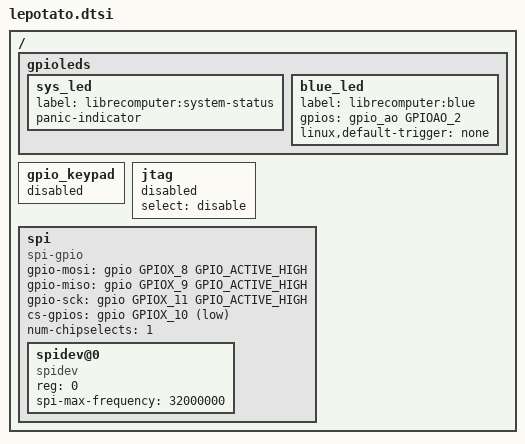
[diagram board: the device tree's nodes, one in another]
/* Stuff common to le potato */

/ {
	gpioleds {
		sys_led {
			label = "librecomputer:system-status";
			panic-indicator;
		};

		blue_led {
			label = "librecomputer:blue";
			gpios = <&gpio_ao GPIOAO_2 GPIO_ACTIVE_HIGH>;
			linux,default-trigger = "none";
		};
	};

	gpio_keypad {
		status = "disabled";
	};

	/delete-node/ mtd_nand;

	jtag {
		status = "disabled";
		select = "disable";
	};

	spi {
		compatible = "spi-gpio";
		ranges;

		gpio-mosi = <&gpio GPIOX_8 GPIO_ACTIVE_HIGH>;
		gpio-miso = <&gpio GPIOX_9 GPIO_ACTIVE_HIGH>;
		gpio-sck = <&gpio GPIOX_11 GPIO_ACTIVE_HIGH>;
		cs-gpios = <&gpio GPIOX_10 GPIO_ACTIVE_LOW>;
		num-chipselects = <1>;
		status = "ok";

		spidev@0 {
			compatible = "spidev";
			reg = <0>;
			spi-max-frequency = <32000000>;
			status = "okay";
		};
	};

};
